# STM32C551 register map
File version: 2.1.0
CPU: CM33 r0p4, little endian, MPU, FPU, 4 interrupt priority bits
Registers are 32-bit, read-write, reset 0x0 unless marked. A register's access mark holds for its fields unless they carry their own. Offsets are from the block's base; [hi:lo] are bit positions.

## DAC1 — DAC address block description
Base 0x42028400
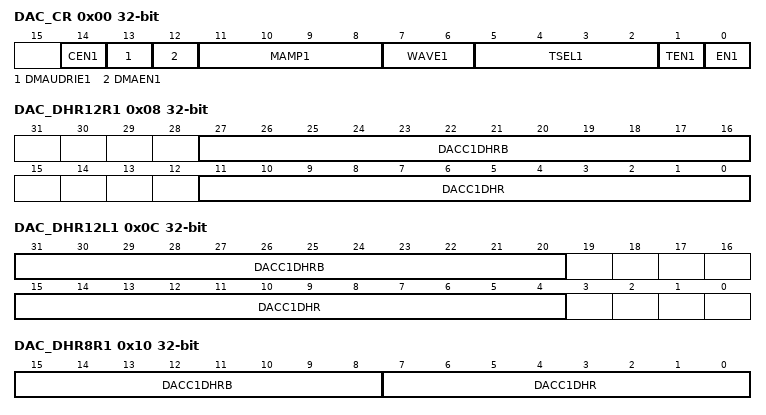
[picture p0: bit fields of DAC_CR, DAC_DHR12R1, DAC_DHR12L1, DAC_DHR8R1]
0x00 DAC_CR — DAC control register
  [14] CEN1 — DAC channel1 calibration enable
    0=DAC channel1 in normal operating mode; 1=DAC channel1 in calibration mode
  [13] DMAUDRIE1 — DAC channel1 DMA Underrun Interrupt enable
    0=DAC channel1 DMA Underrun Interrupt disabled; 1=DAC channel1 DMA Underrun Interrupt enabled
  [12] DMAEN1 — DAC channel1 DMA enable
    0=DAC channel1 DMA mode disabled; 1=DAC channel1 DMA mode enabled
  [11:8] MAMP1 — DAC channel1 mask/amplitude selector
    0=Unmask bit0 of LFSR/ triangle amplitude equal to 1; 1=Unmask bits[1:0] of LFSR/ triangle amplitude equal to 3; 2=Unmask bits[2:0] of LFSR/ triangle amplitude equal to 7; 3=Unmask bits[3:0] of LFSR/ triangle amplitude equal to 15; 4=Unmask bits[4:0] of LFSR/ triangle amplitude equal to 31; 5=Unmask bits[5:0] of LFSR/ triangle amplitude equal to 63; 6=Unmask bits[6:0] of LFSR/ triangle amplitude equal to 127; 7=Unmask bits[7:0] of LFSR/ triangle amplitude equal to 255; 8=Unmask bits[8:0] of LFSR/ triangle amplitude equal to 511; 9=Unmask bits[9:0] of LFSR/ triangle amplitude equal to 1023; 10=Unmask bits[10:0] of LFSR/ triangle amplitude equal to 2047
  [7:6] WAVE1 — DAC channel1 noise/triangle wave generation enable
    0=wave generation disabled; 1=Noise wave generation enabled
  [5:2] TSEL1 — DAC channel1 trigger selection
    0=SWTRIG1; 1=dac_ch1_trg1; 2=dac_ch1_trg2; 15=dac_ch1_trg15
  [1] TEN1 — DAC channel1 trigger enable
    0=DAC channel1 trigger disabled and data written into the DAC_DHR1 register are transferred one dac_hclk clock cycle later to the DAC_DOR1 register; 1=DAC channel1 trigger enabled and data from the DAC_DHR1 register are transferred three dac_hclk clock cycles later to the DAC_DOR1 register
  [0] EN1 — DAC channel1 enable
    0=DAC channel1 disabled; 1=DAC channel1 enabled
0x04 DAC_SWTRGR wo — DAC software trigger register
  [0] SWTRIG1 — DAC channel1 software trigger
    0=No trigger; 1=Trigger
0x08 DAC_DHR12R1 — DAC channel1 12-bit right-aligned data holding register
  [27:16] DACC1DHRB — DAC channel1 12-bit right-aligned data B
  [11:0] DACC1DHR — DAC channel1 12-bit right-aligned data
0x0C DAC_DHR12L1 — DAC channel1 12-bit left aligned data holding register
  [31:20] DACC1DHRB — DAC channel1 12-bit left-aligned data B
  [15:4] DACC1DHR — DAC channel1 12-bit left-aligned data
0x10 DAC_DHR8R1 — DAC channel1 8-bit right aligned data holding register
  [15:8] DACC1DHRB — DAC channel1 8-bit right-aligned data
  [7:0] DACC1DHR — DAC channel1 8-bit right-aligned data
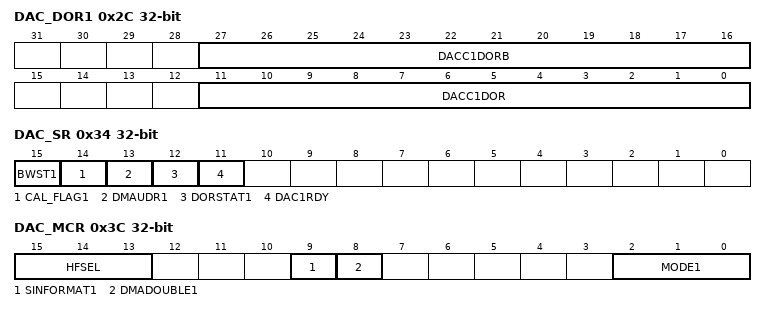
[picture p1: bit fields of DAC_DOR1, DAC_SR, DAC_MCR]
0x2C DAC_DOR1 ro — DAC channel1 data output register
  [27:16] DACC1DORB — DAC channel1 data output
  [11:0] DACC1DOR — DAC channel1 data output
0x34 DAC_SR — DAC status register
  [15] BWST1 ro — DAC channel1 busy writing sample time flag
    0=There is no write operation of DAC_SHSR1 ongoing: DAC_SHSR1 can be written; 1=There is a write operation of DAC_SHSR1 ongoing: DAC_SHSR1 cannot be written
  [14] CAL_FLAG1 ro — DAC channel1 calibration offset status
    0=calibration trimming value is lower than the offset correction value; 1=calibration trimming value is equal or greater than the offset correction value
  [13] DMAUDR1 — DAC channel1 DMA underrun flag
    0=No DMA underrun error condition occurred for DAC channel1; 1=DMA underrun error condition occurred for DAC channel1 (the currently selected trigger is driving DAC channel1 conversion at a frequency higher than the DMA service capability rate)
  [12] DORSTAT1 ro — DAC channel1 output register status bit
    0=DOR[11:0] is used actual DAC output; 1=DORB[11:0] is used actual DAC output
  [11] DAC1RDY ro — DAC channel1 ready status bit
    0=DAC channel1 is not yet ready to accept the trigger nor output data; 1=DAC channel1 is ready to accept the trigger or output data
0x38 DAC_CCR (reset mask 0xFFFFFF00) — DAC calibration control register
  [4:0] OTRIM1 — DAC channel1 offset trimming value
0x3C DAC_MCR — DAC mode control register
  [15:13] HFSEL — High frequency interface mode selection
    0=High frequency interface mode disabled; 1=High frequency interface mode enabled for 80MHzless than or equal todac_ker_ckless than or equal toxA0MHz
  [9] SINFORMAT1 — Enable signed format for DAC channel1
    0=Input data is in unsigned format; 1=Input data is in signed format (2's complement)
  [8] DMADOUBLE1 — DAC channel1 DMA double data mode
    0=DMA normal mode selected; 1=DMA double data mode selected
  [2:0] MODE1 — DAC channel1 mode
    0=DAC channel1 is connected to external pin with Buffer enabled; 1=DAC channel1 is connected to external pin and to on chip peripherals with Buffer enabled; 2=DAC channel1 is connected to external pin with Buffer disabled; 3=DAC channel1 is connected to on chip peripherals with Buffer disabled; 4=DAC channel1 is connected to external pin with Buffer enabled; 5=DAC channel1 is connected to external pin and to on chip peripherals with Buffer enabled; 6=DAC channel1 is connected to external pin and to on chip peripherals with Buffer disabled; 7=DAC channel1 is connected to on chip peripherals with Buffer disabled
0x40 DAC_SHSR1 — DAC channel1 sample and hold sample time register
  [9:0] TSAMPLE1 — DAC channel1 sample time (only valid in sample and hold mode)
0x48 DAC_SHHR reset 0x10001 — DAC sample and hold time register
  [9:0] THOLD1 — DAC channel1 hold time (only valid in sample and hold mode)
0x4C DAC_SHRR reset 0x10001 — DAC sample and hold refresh time register
  [7:0] TREFRESH1 — DAC channel1 refresh time (only valid in sample and hold mode)

## Notices in the file
Copyright (c) 2026 STMicroelectronics.
SPDX-License-Identifier: Apache-2.0
Licensed under the Apache License, Version 2.0 (the "License");
you may not use this file except in compliance with the License.
You may obtain a copy of the License at
http://www.apache.org/licenses/LICENSE-2.0
Unless required by applicable law or agreed to in writing, software
distributed under the License is distributed on an "AS IS" BASIS,
WITHOUT WARRANTIES OR CONDITIONS OF ANY KIND, either express or implied.
See the License for the specific language governing permissions and
limitations under the License.
